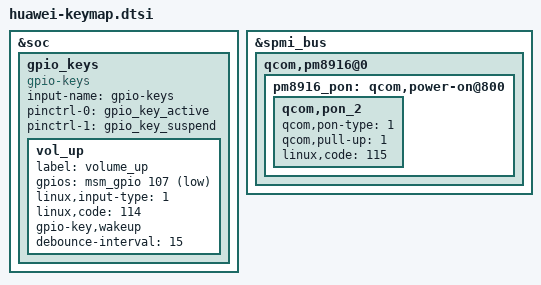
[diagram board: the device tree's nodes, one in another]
&soc {
        gpio_keys {
                compatible = "gpio-keys";
                input-name = "gpio-keys";
                pinctrl-names = "tlmm_gpio_key_active","tlmm_gpio_key_suspend";
                pinctrl-0 = <&gpio_key_active>;
                pinctrl-1 = <&gpio_key_suspend>;

                vol_up {
                        label = "volume_up";
                        gpios = <&msm_gpio 107 0x1>;
                        linux,input-type = <1>;
                        linux,code = <114>;
                        gpio-key,wakeup;
                        debounce-interval = <15>;
                };
        };
};
&spmi_bus {

	qcom,pm8916@0 {
		pm8916_pon: qcom,power-on@800 {

			qcom,pon_2 {
				qcom,pon-type = <1>;
				qcom,pull-up = <1>;
				linux,code = <115>;
			};
		};
	};
};
